# STM32C562 register map
File version: 2.1.0
CPU: CM33 r0p4, little endian, MPU, FPU, 4 interrupt priority bits
Registers are 32-bit, read-write, reset 0x0 unless marked. A register's access mark holds for its fields unless they carry their own. Offsets are from the block's base; [hi:lo] are bit positions; {n}, {i} and the like mark numbered series; 'fields as' and 'values as' point back to an identical list.

## TIM6 — TIM address block description
Base 0x40001000
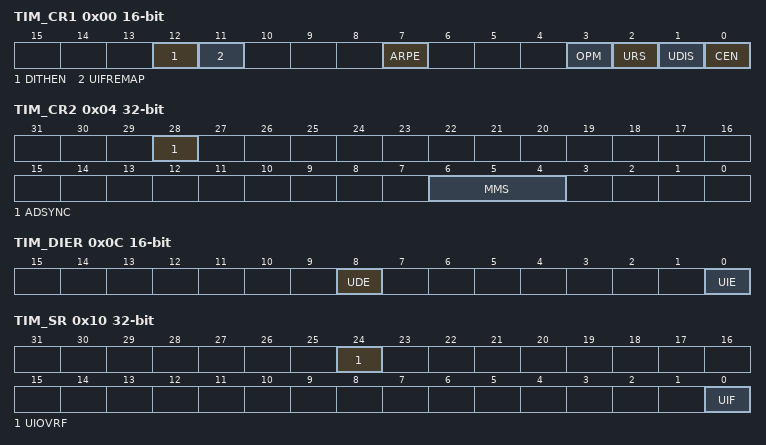
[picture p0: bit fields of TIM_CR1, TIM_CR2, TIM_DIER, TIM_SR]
0x00 TIM_CR1 16-bit — TIM control register 1
  [12] DITHEN — Dithering enable
    0=Dithering disabled; 1=Dithering enabled
  [11] UIFREMAP — UIF status bit remapping
    0=No remapping; 1=Remapping enabled
  [7] ARPE — Auto-reload preload enable
    0=TIMx_ARR register is not buffered; 1=TIMx_ARR register is buffered
  [3] OPM — One-pulse mode
    0=Counter is not stopped at update event; 1=Counter stops counting at the next update event (clearing the CEN bit)
  [2] URS — Update request source
    0=Any of the following events generates an update interrupt or DMA request if enabled; 1=Only counter overflow/underflow generates an update interrupt or DMA request if enabled
  [1] UDIS — Update disable
    0=UEV enabled; 1=UEV disabled
  [0] CEN — Counter enable
    0=Counter disabled; 1=Counter enabled
0x04 TIM_CR2 — TIM control register 2
  [28] ADSYNC — ADC synchronization
    0=The timer operates independently from the ADC; 1=The timer operation is synchronized with the ADC clock to provide jitter-free sampling point
  [6:4] MMS — Master mode selection
    0=Reset - the UG bit from the TIMx_EGR register is used as a trigger output (tim_trgo); 1=Enable - the Counter enable signal, tim_cnt_en, is used as a trigger output (tim_trgo); 2=Update - The update event is selected as a trigger output (tim_trgo)
0x0C TIM_DIER 16-bit — TIM DMA/Interrupt enable register
  [8] UDE — Update DMA request enable
    0=Update DMA request disabled; 1=Update DMA request enabled
  [0] UIE — Update interrupt enable
    0=Update interrupt disabled; 1=Update interrupt enabled
0x10 TIM_SR — TIM status register
  [24] UIOVRF — Update Interrupt Overrun flag
    0=No Update Interrupt Overrun; 1=Update Interrupt Overrun
  [0] UIF — Update interrupt flag
    0=No update occurred; 1=Update interrupt pending
0x14 TIM_EGR 16-bit — TIM event generation register
  [0] UG wo — Update generation
    0=No action; 1=Re-initializes the timer counter and generates an update of the registers
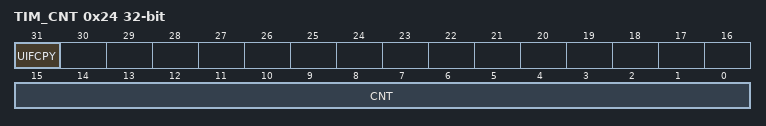
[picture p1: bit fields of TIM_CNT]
0x24 TIM_CNT — TIM counter
  [31] UIFCPY ro — UIF copy
  [15:0] CNT — Counter value
0x28 TIM_PSC 16-bit — TIM prescaler
  [15:0] PSC — Prescaler value
0x2C TIM_ARR reset 0xFFFF — TIM6 autoreload register
  [19:0] ARR — Auto-reload value

## TIM7 — TIM address block description
Base 0x40001400
Registers as TIM6; these are added or differ:
0x2C TIM_ARR reset 0xFFFF — TIM autoreload register
  [19:0] ARR — Auto-reload value

## USBSRAM — USBSRAM address block description
Base 0x40016400
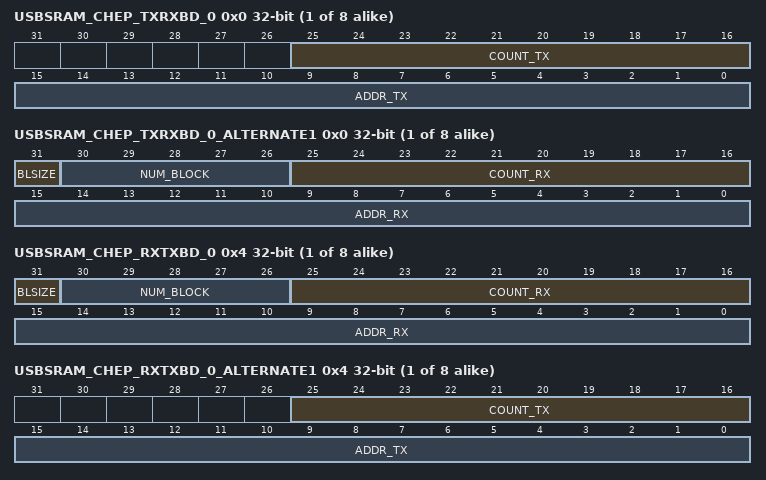
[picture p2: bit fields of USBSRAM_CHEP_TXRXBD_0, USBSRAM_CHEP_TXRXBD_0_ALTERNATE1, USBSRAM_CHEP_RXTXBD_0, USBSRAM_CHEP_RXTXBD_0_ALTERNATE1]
{0x0+8i} USBSRAM_CHEP_TXRXBD_{i} reset not defined (i=0..7) — Channel/endpoint transmit buffer descriptor {i}
  [25:16] COUNT_TX — Transmission byte count
  [15:0] ADDR_TX — Transmission buffer address
{0x0+8i} USBSRAM_CHEP_TXRXBD_{i}_ALTERNATE1 reset not defined (alternate view of USBSRAM_CHEP_TXRXBD_{i}) (i=0..7) — Channel/endpoint receive buffer descriptor {i}
  [31] BLSIZE — Block size
  [30:26] NUM_BLOCK — Number of blocks
  [25:16] COUNT_RX — Reception byte count
  [15:0] ADDR_RX — Reception buffer address
{0x4+8i} USBSRAM_CHEP_RXTXBD_{i} reset not defined (i=0..7) — Channel/endpoint receive buffer descriptor {i}
  fields as USBSRAM_CHEP_TXRXBD_0_ALTERNATE1
{0x4+8i} USBSRAM_CHEP_RXTXBD_{i}_ALTERNATE1 reset not defined (alternate view of USBSRAM_CHEP_RXTXBD_{i}) (i=0..7) — Channel/endpoint transmit buffer descriptor {i}
  fields as USBSRAM_CHEP_TXRXBD_0

## WWDG — System window watchdog
Base 0x40002C00
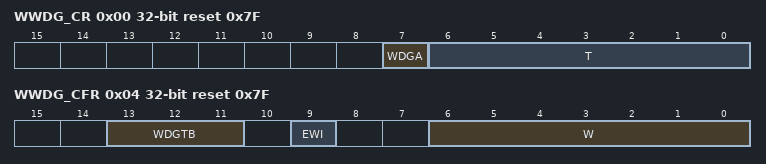
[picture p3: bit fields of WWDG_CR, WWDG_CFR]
0x00 WWDG_CR reset 0x7F — WWDG control register
  [7] WDGA — Activation bit This bit is set by software and only cleared by hardware after a reset. When WDGA = 1, the watchdog can generate a reset.
    0=Watchdog disabled; 1=Watchdog enabled
  [6:0] T — 7-bit counter (MSB to LSB) These bits contain the value of the watchdog counter, decremented every (4096 x 2WDGTB[2:0]) PCLK cycles. A reset is produced when it is decremented from 0x40 to 0x3F (T6 becomes cleared).
0x04 WWDG_CFR reset 0x7F — WWDG configuration register
  [13:11] WDGTB — Timer base The timebase of the prescaler can be modified as follows:
    0=CK counter clock (PCLK div 4096) div 1; 1=CK counter clock (PCLK div 4096) div 2; 2=CK counter clock (PCLK div 4096) div 4; 3=CK counter clock (PCLK div 4096) div 8; 4=CK counter clock (PCLK div 4096) div 16; 5=CK counter clock (PCLK div 4096) div 32; 6=CK counter clock (PCLK div 4096) div 64; 7=CK counter clock (PCLK div 4096) div 128
  [9] EWI — Early wakeup interrupt When set, an interrupt occurs whenever the counter reaches the value 0x40. This interrupt is only cleared by hardware after a reset.
  [6:0] W — 7-bit window value These bits contain the window value to be compared with the down-counter.
0x08 WWDG_SR — WWDG status register
  [0] EWIF — Early wakeup interrupt flag This bit is set by hardware when the counter has reached the value 0x40. It must be cleared by software by writing 0. Writing 1 has no effect. This bit is also set if the interrupt is not enabled.
